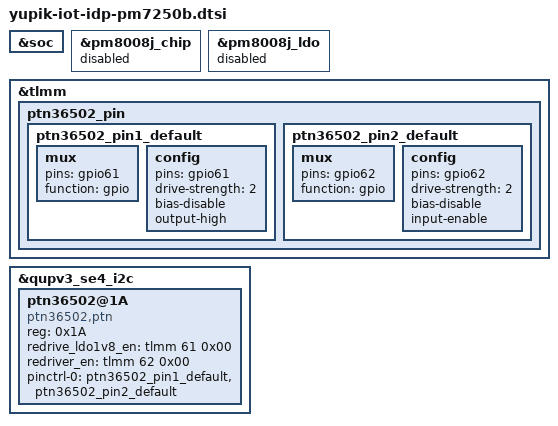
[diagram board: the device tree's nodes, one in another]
#include "yupik-idp-pm7250b.dtsi"


&soc {

};


&pm8008j_chip {
	status = "disabled";
};

&pm8008j_ldo {
	status = "disabled";
};


&tlmm {
		ptn36502_pin {
			ptn36502_pin1_default: ptn36502_pin1_default{
				mux {
                        pins = "gpio61";
                        function = "gpio";
				};

				config {
                            pins = "gpio61";
                            drive-strength = <2>;
                            bias-disable;
                            output-high;
				};
			};

			ptn36502_pin2_default: ptn36502_pin2_default{
				mux {
                        pins = "gpio62";
                        function = "gpio";
				};

				config {
                            pins = "gpio62";
                            drive-strength = <2>;
                            bias-disable;
                            input-enable;
				};
			};


		};
};



&qupv3_se4_i2c {
	#address-cells = <1>;
	#size-cells = <0>;
	status = "ok";

	ptn36502@1A {
		compatible = "ptn36502,ptn";
		reg = <0x1A>;
        redrive_ldo1v8_en = <&tlmm 61  0x00>;
        redriver_en = <&tlmm 62  0x00>;
		pinctrl-names = "default";
		pinctrl-0 = <&ptn36502_pin1_default &ptn36502_pin2_default>;
		status = "ok";
	};
};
